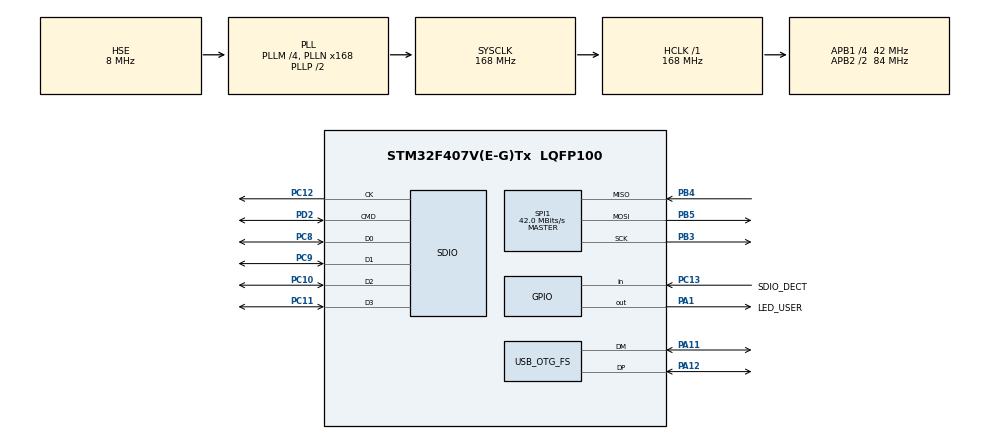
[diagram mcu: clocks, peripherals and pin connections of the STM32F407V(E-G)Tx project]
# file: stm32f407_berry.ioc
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FATFS.BSP.number=1
FATFS._CODE_PAGE=437
FATFS._FS_RPATH=2
FATFS._STRF_ENCODE=0
FATFS._USE_LFN=3
FATFS0.BSP.STBoard=false
FATFS0.BSP.api=Unknown
FATFS0.BSP.i2caddr=0
FATFS0.BSP.instance=PC13-ANTI_TAMP
FATFS0.BSP.ip=GPIO
FATFS0.BSP.mode=Input
FATFS0.BSP.name=Detect_SDIO
FATFS0.BSP.solution=PC13-ANTI_TAMP
Mcu.Family=STM32F4
Mcu.Name=STM32F407V(E-G)Tx
Mcu.Package=LQFP100
NVIC.OTG_FS_IRQn=true\:0\:0\:false\:false\:true\:false\:true
NVIC.PriorityGroup=NVIC_PRIORITYGROUP_4
PA1.GPIO_Label=LED_USER
PA1.Signal=GPIO_Output
PA11.Mode=Device_Only
PA11.Signal=USB_OTG_FS_DM
PA12.Mode=Device_Only
PA12.Signal=USB_OTG_FS_DP
PA15.Signal=SPI1_NSS
PB3.Mode=Full_Duplex_Master
PB3.Signal=SPI1_SCK
PB4.Mode=Full_Duplex_Master
PB4.Signal=SPI1_MISO
PB5.Mode=Full_Duplex_Master
PB5.Signal=SPI1_MOSI
PC10.Mode=SD_4_bits_Wide_bus
PC10.Signal=SDIO_D2
PC11.Mode=SD_4_bits_Wide_bus
PC11.Signal=SDIO_D3
PC12.Mode=SD_4_bits_Wide_bus
PC12.Signal=SDIO_CK
PC13-ANTI_TAMP.GPIO_Label=SDIO_DECT
PC13-ANTI_TAMP.Signal=GPIO_Input
PC14-OSC32_IN.Mode=LSE-External-Oscillator
PC14-OSC32_IN.Signal=RCC_OSC32_IN
PC15-OSC32_OUT.Mode=LSE-External-Oscillator
PC15-OSC32_OUT.Signal=RCC_OSC32_OUT
PC8.Mode=SD_4_bits_Wide_bus
PC8.Signal=SDIO_D0
PC9.Mode=SD_4_bits_Wide_bus
PC9.Signal=SDIO_D1
PD2.Mode=SD_4_bits_Wide_bus
PD2.Signal=SDIO_CMD
PH0-OSC_IN.Mode=HSE-External-Oscillator
PH0-OSC_IN.Signal=RCC_OSC_IN
PH1-OSC_OUT.Mode=HSE-External-Oscillator
PH1-OSC_OUT.Signal=RCC_OSC_OUT
ProjectManager.HeapSize=0x10000
ProjectManager.StackSize=0x2000
ProjectManager.TargetToolchain=MDK-ARM V5
RCC.48MHZClocksFreq_Value=48000000
RCC.AHBFreq_Value=168000000
RCC.APB1CLKDivider=RCC_HCLK_DIV4
RCC.APB1Freq_Value=42000000
RCC.APB1TimFreq_Value=84000000
RCC.APB2CLKDivider=RCC_HCLK_DIV2
RCC.APB2Freq_Value=84000000
RCC.APB2TimFreq_Value=168000000
RCC.CortexFreq_Value=168000000
RCC.HCLKFreq_Value=168000000
RCC.HSE_VALUE=8000000
RCC.HSI_VALUE=16000000
RCC.PLLM=4
RCC.PLLN=168
RCC.PLLQ=7
RCC.SYSCLKFreq_VALUE=168000000
RCC.SYSCLKSource=RCC_SYSCLKSOURCE_PLLCLK
RCC.VCOOutputFreq_Value=336000000
SDIO.ClockBypass=SDIO_CLOCK_BYPASS_ENABLE
SDIO.ClockDiv=15
SDIO.ClockPowerSave=SDIO_CLOCK_POWER_SAVE_ENABLE
SPI1.CalculateBaudRate=42.0 MBits/s
SPI1.Direction=SPI_DIRECTION_2LINES
SPI1.Mode=SPI_MODE_MASTER
SPI1.VirtualType=VM_MASTER
USB_DEVICE.APP_RX_DATA_SIZE-CDC_FS=256
USB_DEVICE.APP_TX_DATA_SIZE-CDC_FS=256
USB_DEVICE.CLASS_NAME_FS=CDC
USB_DEVICE.MANUFACTURER_STRING-CDC_FS=STMicroelectronics
USB_DEVICE.USBD_MAX_STR_DESC_SIZ-CDC_FS=64
USB_DEVICE.VirtualMode-CDC_FS=Cdc
USB_DEVICE.VirtualModeFS=Cdc_FS
USB_OTG_FS.VirtualMode=Device_Only
VP_FATFS_VS_SDIO.Mode=SDIO
VP_USB_DEVICE_VS_USB_DEVICE_CDC_FS.Mode=CDC_FS
board=custom

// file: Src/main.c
/* USER CODE BEGIN Header */
/**
  ******************************************************************************
  * @file           : main.c
  * @brief          : Main program body
  ******************************************************************************
  * @attention
  *
  * <h2><center>&copy; Copyright (c) 2019 STMicroelectronics.
  * All rights reserved.</center></h2>
  *
  * This software component is licensed by ST under BSD 3-Clause license,
  * the "License"; You may not use this file except in compliance with the
  * License. You may obtain a copy of the License at:
  *                        opensource.org/licenses/BSD-3-Clause
  *
  ******************************************************************************
  */
/* USER CODE END Header */

#include "main.h"
#include "fatfs.h"
#include "usb_device.h"

SD_HandleTypeDef hsd;

SPI_HandleTypeDef hspi1;

void SystemClock_Config(void);
static void MX_GPIO_Init(void);
static void MX_SDIO_SD_Init(void);
static void MX_SPI1_Init(void);
/* USER CODE BEGIN PFP */
extern int berry_main(int argc, char *argv[]);
/* USER CODE END PFP */

int main(void)
{

  /* MCU Configuration--------------------------------------------------------*/

  /* Reset of all peripherals, Initializes the Flash interface and the Systick. */
  HAL_Init();

  /* Configure the system clock */
  SystemClock_Config();

  /* Initialize all configured peripherals */
  MX_GPIO_Init();
  MX_USB_DEVICE_Init();
  MX_SDIO_SD_Init();
  MX_SPI1_Init();
  MX_FATFS_Init();
  /* USER CODE BEGIN 2 */
  berry_main(0, NULL);
  /* USER CODE END 2 */

  /* Infinite loop */
  while (1)
  {

  }
}

void SystemClock_Config(void)
{
  RCC_OscInitTypeDef RCC_OscInitStruct = {0};
  RCC_ClkInitTypeDef RCC_ClkInitStruct = {0};

  /** Configure the main internal regulator output voltage
  */
  __HAL_RCC_PWR_CLK_ENABLE();
  __HAL_PWR_VOLTAGESCALING_CONFIG(PWR_REGULATOR_VOLTAGE_SCALE1);
  /** Initializes the CPU, AHB and APB busses clocks
  */
  RCC_OscInitStruct.OscillatorType = RCC_OSCILLATORTYPE_HSE;
  RCC_OscInitStruct.HSEState = RCC_HSE_ON;
  RCC_OscInitStruct.PLL.PLLState = RCC_PLL_ON;
  RCC_OscInitStruct.PLL.PLLSource = RCC_PLLSOURCE_HSE;
  RCC_OscInitStruct.PLL.PLLM = 4;
  RCC_OscInitStruct.PLL.PLLN = 168;
  RCC_OscInitStruct.PLL.PLLP = RCC_PLLP_DIV2;
  RCC_OscInitStruct.PLL.PLLQ = 7;
  if (HAL_RCC_OscConfig(&RCC_OscInitStruct) != HAL_OK)
  {
    Error_Handler();
  }
  /** Initializes the CPU, AHB and APB busses clocks
  */
  RCC_ClkInitStruct.ClockType = RCC_CLOCKTYPE_HCLK|RCC_CLOCKTYPE_SYSCLK
                              |RCC_CLOCKTYPE_PCLK1|RCC_CLOCKTYPE_PCLK2;
  RCC_ClkInitStruct.SYSCLKSource = RCC_SYSCLKSOURCE_PLLCLK;
  RCC_ClkInitStruct.AHBCLKDivider = RCC_SYSCLK_DIV1;
  RCC_ClkInitStruct.APB1CLKDivider = RCC_HCLK_DIV4;
  RCC_ClkInitStruct.APB2CLKDivider = RCC_HCLK_DIV2;

  if (HAL_RCC_ClockConfig(&RCC_ClkInitStruct, FLASH_LATENCY_5) != HAL_OK)
  {
    Error_Handler();
  }
}

static void MX_SDIO_SD_Init(void)
{

  hsd.Instance = SDIO;
  hsd.Init.ClockEdge = SDIO_CLOCK_EDGE_RISING;
  hsd.Init.ClockBypass = SDIO_CLOCK_BYPASS_ENABLE;
  hsd.Init.ClockPowerSave = SDIO_CLOCK_POWER_SAVE_ENABLE;
  hsd.Init.BusWide = SDIO_BUS_WIDE_1B;
  hsd.Init.HardwareFlowControl = SDIO_HARDWARE_FLOW_CONTROL_DISABLE;
  hsd.Init.ClockDiv = 15;

}

static void MX_SPI1_Init(void)
{

  /* SPI1 parameter configuration*/
  hspi1.Instance = SPI1;
  hspi1.Init.Mode = SPI_MODE_MASTER;
  hspi1.Init.Direction = SPI_DIRECTION_2LINES;
  hspi1.Init.DataSize = SPI_DATASIZE_8BIT;
  hspi1.Init.CLKPolarity = SPI_POLARITY_LOW;
  hspi1.Init.CLKPhase = SPI_PHASE_1EDGE;
  hspi1.Init.NSS = SPI_NSS_SOFT;
  hspi1.Init.BaudRatePrescaler = SPI_BAUDRATEPRESCALER_2;
  hspi1.Init.FirstBit = SPI_FIRSTBIT_MSB;
  hspi1.Init.TIMode = SPI_TIMODE_DISABLE;
  hspi1.Init.CRCCalculation = SPI_CRCCALCULATION_DISABLE;
  hspi1.Init.CRCPolynomial = 10;
  if (HAL_SPI_Init(&hspi1) != HAL_OK)
  {
    Error_Handler();
  }

}

static void MX_GPIO_Init(void)
{
  GPIO_InitTypeDef GPIO_InitStruct = {0};

  /* GPIO Ports Clock Enable */
  __HAL_RCC_GPIOC_CLK_ENABLE();
  __HAL_RCC_GPIOH_CLK_ENABLE();
  __HAL_RCC_GPIOA_CLK_ENABLE();
  __HAL_RCC_GPIOD_CLK_ENABLE();
  __HAL_RCC_GPIOB_CLK_ENABLE();

  /*Configure GPIO pin Output Level */
  HAL_GPIO_WritePin(LED_USER_GPIO_Port, LED_USER_Pin, GPIO_PIN_RESET);

  /*Configure GPIO pin : SDIO_DECT_Pin */
  GPIO_InitStruct.Pin = SDIO_DECT_Pin;
  GPIO_InitStruct.Mode = GPIO_MODE_INPUT;
  GPIO_InitStruct.Pull = GPIO_NOPULL;
  HAL_GPIO_Init(SDIO_DECT_GPIO_Port, &GPIO_InitStruct);

  /*Configure GPIO pin : LED_USER_Pin */
  GPIO_InitStruct.Pin = LED_USER_Pin;
  GPIO_InitStruct.Mode = GPIO_MODE_OUTPUT_PP;
  GPIO_InitStruct.Pull = GPIO_NOPULL;
  GPIO_InitStruct.Speed = GPIO_SPEED_FREQ_LOW;
  HAL_GPIO_Init(LED_USER_GPIO_Port, &GPIO_InitStruct);

}

void Error_Handler(void)
{
}

/************************ (C) COPYRIGHT STMicroelectronics *****END OF FILE****/
